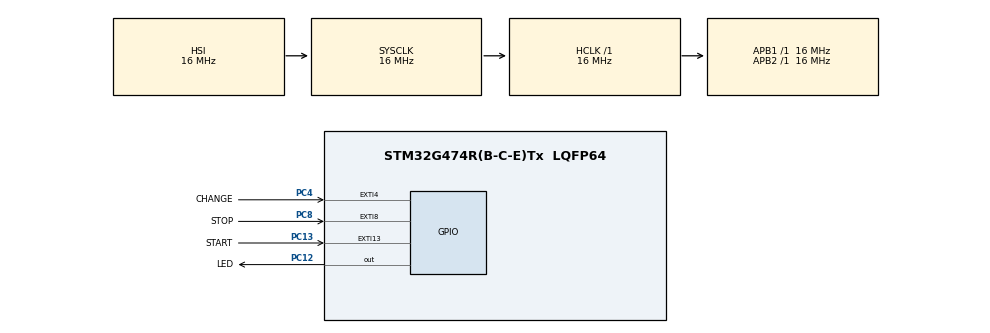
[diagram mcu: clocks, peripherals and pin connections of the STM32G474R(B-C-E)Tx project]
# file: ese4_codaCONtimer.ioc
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Mcu.Family=STM32G4
Mcu.Name=STM32G474R(B-C-E)Tx
Mcu.Package=LQFP64
NVIC.EXTI15_10_IRQn=true\:0\:0\:false\:false\:true\:true\:true\:true
NVIC.EXTI4_IRQn=true\:0\:0\:false\:false\:true\:true\:true\:true
NVIC.EXTI9_5_IRQn=true\:0\:0\:false\:false\:true\:true\:true\:true
NVIC.PriorityGroup=NVIC_PRIORITYGROUP_4
NVIC.TIM6_DAC_IRQn=true\:0\:0\:false\:false\:true\:true\:true\:true
NVIC.TIM7_DAC_IRQn=true\:0\:0\:false\:false\:true\:true\:true\:true
PC12.GPIO_Label=LED
PC12.Signal=GPIO_Output
PC13.GPIO_Label=START
PC13.GPIO_ModeDefaultEXTI=GPIO_MODE_IT_FALLING
PC13.Signal=GPXTI13
PC4.GPIO_Label=CHANGE
PC4.GPIO_ModeDefaultEXTI=GPIO_MODE_IT_FALLING
PC4.Signal=GPXTI4
PC8.GPIO_Label=STOP
PC8.GPIO_ModeDefaultEXTI=GPIO_MODE_IT_FALLING
PC8.Signal=GPXTI8
ProjectManager.HeapSize=0x200
ProjectManager.StackSize=0x400
ProjectManager.TargetToolchain=STM32CubeIDE
RCC.AHBFreq_Value=16000000
RCC.APB1Freq_Value=16000000
RCC.APB1TimFreq_Value=16000000
RCC.APB2Freq_Value=16000000
RCC.APB2TimFreq_Value=16000000
RCC.CortexFreq_Value=16000000
RCC.EXTERNAL_CLOCK_VALUE=12288000
RCC.HCLKFreq_Value=16000000
RCC.HSE_VALUE=8000000
RCC.HSI48_VALUE=48000000
RCC.HSI_VALUE=16000000
RCC.LSE_VALUE=32768
RCC.SYSCLKFreq_VALUE=16000000
RCC.USBFreq_Value=64000000
RCC.VCOOutputFreq_Value=128000000
TIM6.PeriodNoDither=999
TIM6.Prescaler=15999
TIM7.PeriodNoDither=999
TIM7.Prescaler=15999
VP_SYS_VS_DBSignals.Mode=DisableDeadBatterySignals
VP_TIM6_VS_ClockSourceINT.Mode=Enable_Timer
VP_TIM7_VS_ClockSourceINT.Mode=Enable_Timer
board=custom

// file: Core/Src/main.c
/* USER CODE BEGIN Header */
/**
  ******************************************************************************
  * @file           : main.c
  * @brief          : Main program body
  ******************************************************************************
  * @attention
  *
  * Copyright (c) 2026 STMicroelectronics.
  * All rights reserved.
  *
  * This software is licensed under terms that can be found in the LICENSE file
  * in the root directory of this software component.
  * If no LICENSE file comes with this software, it is provided AS-IS.
  *
  ******************************************************************************
  */
/* USER CODE END Header */
#include "main.h"
#include "tim.h"
#include "gpio.h"

/* USER CODE BEGIN Includes */
#include "queue.h"

/* USER CODE END Includes */

/* USER CODE BEGIN PD */
#define MAX_QUEUE_STORAGE 10

/* USER CODE END PD */

/* USER CODE BEGIN PV */
queue_t my_queue; //oggetto coda
uint8_t my_queue_storage[MAX_QUEUE_STORAGE* sizeof(uint8_t)]; //buffer della nostra coda con allocati i byte massimi che contiene la coda

/* USER CODE END PV */

void SystemClock_Config(void);

int main(void)
{

  /* MCU Configuration--------------------------------------------------------*/

  /* Reset of all peripherals, Initializes the Flash interface and the Systick. */
  HAL_Init();

  /* Configure the system clock */
  SystemClock_Config();

  /* Initialize all configured peripherals */
  MX_GPIO_Init();
  MX_TIM6_Init();
  MX_TIM7_Init();
  /* USER CODE BEGIN 2 */
  //queue_init(queue_t* queue, uint8_t* queue_buffer, uint16_t items_size, uint16_t queue_size)
  if(queue_init(&my_queue, my_queue_storage,sizeof(uint8_t), MAX_QUEUE_STORAGE)!=QUEUE_OK){
	  Error_Handler();
  }
  HAL_TIM_Base_Start_IT(&htim7);

  /* USER CODE END 2 */

  /* Infinite loop */
  while (1)
  {

  }
}

void SystemClock_Config(void)
{
  RCC_OscInitTypeDef RCC_OscInitStruct = {0};
  RCC_ClkInitTypeDef RCC_ClkInitStruct = {0};

  /** Configure the main internal regulator output voltage
  */
  HAL_PWREx_ControlVoltageScaling(PWR_REGULATOR_VOLTAGE_SCALE1);

  /** Initializes the RCC Oscillators according to the specified parameters
  * in the RCC_OscInitTypeDef structure.
  */
  RCC_OscInitStruct.OscillatorType = RCC_OSCILLATORTYPE_HSI;
  RCC_OscInitStruct.HSIState = RCC_HSI_ON;
  RCC_OscInitStruct.HSICalibrationValue = RCC_HSICALIBRATION_DEFAULT;
  RCC_OscInitStruct.PLL.PLLState = RCC_PLL_NONE;
  if (HAL_RCC_OscConfig(&RCC_OscInitStruct) != HAL_OK)
  {
    Error_Handler();
  }

  /** Initializes the CPU, AHB and APB buses clocks
  */
  RCC_ClkInitStruct.ClockType = RCC_CLOCKTYPE_HCLK|RCC_CLOCKTYPE_SYSCLK
                              |RCC_CLOCKTYPE_PCLK1|RCC_CLOCKTYPE_PCLK2;
  RCC_ClkInitStruct.SYSCLKSource = RCC_SYSCLKSOURCE_HSI;
  RCC_ClkInitStruct.AHBCLKDivider = RCC_SYSCLK_DIV1;
  RCC_ClkInitStruct.APB1CLKDivider = RCC_HCLK_DIV1;
  RCC_ClkInitStruct.APB2CLKDivider = RCC_HCLK_DIV1;

  if (HAL_RCC_ClockConfig(&RCC_ClkInitStruct, FLASH_LATENCY_0) != HAL_OK)
  {
    Error_Handler();
  }
}

void Error_Handler(void)
{
  __disable_irq();
  while (1)
  {
  }
}
